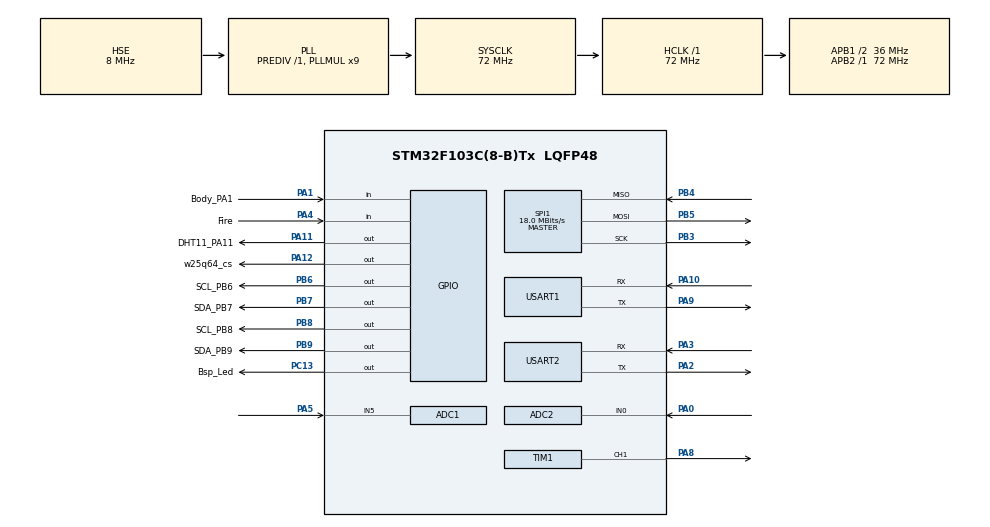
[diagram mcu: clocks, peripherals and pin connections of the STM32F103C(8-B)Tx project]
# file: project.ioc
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ADC1.Channel-6\#ChannelRegularConversion=ADC_CHANNEL_5
ADC1.ContinuousConvMode=DISABLE
ADC1.NbrOfConversionFlag=1
ADC1.Rank-6\#ChannelRegularConversion=1
ADC1.SamplingTime-6\#ChannelRegularConversion=ADC_SAMPLETIME_28CYCLES_5
ADC1.master=1
ADC2.Channel-0\#ChannelRegularConversion=ADC_CHANNEL_0
ADC2.ContinuousConvMode=DISABLE
ADC2.NbrOfConversionFlag=1
ADC2.Rank-0\#ChannelRegularConversion=1
ADC2.SamplingTime-0\#ChannelRegularConversion=ADC_SAMPLETIME_55CYCLES_5
Dma.Request0=USART1_RX
Dma.USART1_RX.0.Direction=DMA_PERIPH_TO_MEMORY
Dma.USART1_RX.0.Instance=DMA1_Channel5
Dma.USART1_RX.0.MemDataAlignment=DMA_MDATAALIGN_BYTE
Dma.USART1_RX.0.MemInc=DMA_MINC_ENABLE
Dma.USART1_RX.0.Mode=DMA_NORMAL
Dma.USART1_RX.0.PeriphDataAlignment=DMA_PDATAALIGN_BYTE
Dma.USART1_RX.0.PeriphInc=DMA_PINC_DISABLE
Dma.USART1_RX.0.Priority=DMA_PRIORITY_MEDIUM
FREERTOS.Tasks01=All_TaskInit,24,128,Start_TaskInit,Default,NULL,Dynamic,NULL,NULL
FREERTOS.configCHECK_FOR_STACK_OVERFLOW=2
FREERTOS.configTOTAL_HEAP_SIZE=12*1024
FREERTOS.configUSE_IDLE_HOOK=1
FREERTOS.configUSE_STATS_FORMATTING_FUNCTIONS=1
Mcu.Family=STM32F1
Mcu.Name=STM32F103C(8-B)Tx
Mcu.Package=LQFP48
NVIC.DMA1_Channel5_IRQn=true\:5\:0\:false\:false\:true\:true\:false\:true\:true
NVIC.PriorityGroup=NVIC_PRIORITYGROUP_4
NVIC.TIM2_IRQn=true\:5\:0\:false\:false\:true\:true\:true\:true\:true
NVIC.TIM4_IRQn=true\:0\:0\:true\:false\:true\:false\:false\:true\:true
NVIC.TimeBase=TIM4_IRQn
NVIC.TimeBaseIP=TIM4
NVIC.USART1_IRQn=true\:5\:0\:false\:false\:true\:true\:true\:true\:true
NVIC.USART2_IRQn=true\:5\:0\:false\:false\:true\:true\:true\:true\:true
PA0-WKUP.Signal=ADCx_IN0
PA1.GPIO_Label=Body_PA1
PA1.GPIO_PuPd=GPIO_PULLDOWN
PA1.Signal=GPIO_Input
PA10.Mode=Asynchronous
PA10.Signal=USART1_RX
PA11.GPIO_Label=DHT11_PA11
PA11.GPIO_ModeDefaultOutputPP=GPIO_MODE_OUTPUT_PP
PA11.GPIO_PuPd=GPIO_NOPULL
PA11.Signal=GPIO_Output
PA12.GPIO_Label=w25q64_cs
PA12.GPIO_PuPd=GPIO_PULLUP
PA12.GPIO_Speed=GPIO_SPEED_FREQ_HIGH
PA12.PinState=GPIO_PIN_SET
PA12.Signal=GPIO_Output
PA13.Mode=Serial_Wire
PA13.Signal=SYS_JTMS-SWDIO
PA14.Mode=Serial_Wire
PA14.Signal=SYS_JTCK-SWCLK
PA2.Mode=Asynchronous
PA2.Signal=USART2_TX
PA3.Mode=Asynchronous
PA3.Signal=USART2_RX
PA4.GPIO_Label=Fire
PA4.GPIO_PuPd=GPIO_PULLUP
PA4.Signal=GPIO_Input
PA5.Signal=ADCx_IN5
PA8.Signal=S_TIM1_CH1
PA9.Mode=Asynchronous
PA9.Signal=USART1_TX
PB3.Mode=Full_Duplex_Master
PB3.Signal=SPI1_SCK
PB4.Mode=Full_Duplex_Master
PB4.Signal=SPI1_MISO
PB5.Mode=Full_Duplex_Master
PB5.Signal=SPI1_MOSI
PB6.GPIO_Label=SCL_PB6
PB6.GPIO_ModeDefaultOutputPP=GPIO_MODE_OUTPUT_OD
PB6.GPIO_PuPd=GPIO_NOPULL
PB6.GPIO_Speed=GPIO_SPEED_FREQ_MEDIUM
PB6.PinState=GPIO_PIN_SET
PB6.Signal=GPIO_Output
PB7.GPIO_Label=SDA_PB7
PB7.GPIO_ModeDefaultOutputPP=GPIO_MODE_OUTPUT_OD
PB7.GPIO_PuPd=GPIO_NOPULL
PB7.GPIO_Speed=GPIO_SPEED_FREQ_MEDIUM
PB7.PinState=GPIO_PIN_SET
PB7.Signal=GPIO_Output
PB8.GPIO_Label=SCL_PB8
PB8.GPIO_ModeDefaultOutputPP=GPIO_MODE_OUTPUT_OD
PB8.GPIO_PuPd=GPIO_NOPULL
PB8.GPIO_Speed=GPIO_SPEED_FREQ_HIGH
PB8.Signal=GPIO_Output
PB9.GPIO_Label=SDA_PB9
PB9.GPIO_ModeDefaultOutputPP=GPIO_MODE_OUTPUT_OD
PB9.GPIO_PuPd=GPIO_NOPULL
PB9.GPIO_Speed=GPIO_SPEED_FREQ_HIGH
PB9.Signal=GPIO_Output
PC13-TAMPER-RTC.GPIO_Label=Bsp_Led
PC13-TAMPER-RTC.GPIO_ModeDefaultOutputPP=GPIO_MODE_OUTPUT_PP
PC13-TAMPER-RTC.GPIO_Speed=GPIO_SPEED_FREQ_MEDIUM
PC13-TAMPER-RTC.PinState=GPIO_PIN_SET
PC13-TAMPER-RTC.Signal=GPIO_Output
PC14-OSC32_IN.Mode=LSE-External-Oscillator
PC14-OSC32_IN.Signal=RCC_OSC32_IN
PC15-OSC32_OUT.Mode=LSE-External-Oscillator
PC15-OSC32_OUT.Signal=RCC_OSC32_OUT
PD0-OSC_IN.Mode=HSE-External-Oscillator
PD0-OSC_IN.Signal=RCC_OSC_IN
PD1-OSC_OUT.Mode=HSE-External-Oscillator
PD1-OSC_OUT.Signal=RCC_OSC_OUT
ProjectManager.HeapSize=0x000
ProjectManager.StackSize=0x400
ProjectManager.TargetToolchain=MDK-ARM V5.32
RCC.ADCPresc=RCC_ADCPCLK2_DIV6
RCC.AHBFreq_Value=72000000
RCC.APB1CLKDivider=RCC_HCLK_DIV2
RCC.APB1Freq_Value=36000000
RCC.APB1TimFreq_Value=72000000
RCC.APB2Freq_Value=72000000
RCC.APB2TimFreq_Value=72000000
RCC.HCLKFreq_Value=72000000
RCC.PLLMUL=RCC_PLL_MUL9
RCC.PLLSourceVirtual=RCC_PLLSOURCE_HSE
RCC.SYSCLKFreq_VALUE=72000000
RCC.SYSCLKSource=RCC_SYSCLKSOURCE_PLLCLK
RCC.USBFreq_Value=72000000
SH.ADCx_IN0.0=ADC2_IN0,IN0
SH.ADCx_IN5.0=ADC1_IN5,IN5
SH.S_TIM1_CH1.0=TIM1_CH1,PWM Generation1 CH1
SPI1.BaudRatePrescaler=SPI_BAUDRATEPRESCALER_4
SPI1.CalculateBaudRate=18.0 MBits/s
SPI1.Direction=SPI_DIRECTION_2LINES
SPI1.Mode=SPI_MODE_MASTER
SPI1.VirtualType=VM_MASTER
TIM1.Channel-PWM\ Generation1\ CH1=TIM_CHANNEL_1
TIM1.Period=1000-1
TIM1.Prescaler=72-1
TIM2.Period=100-1
TIM2.Prescaler=7200-1
USART1.VirtualMode=VM_ASYNC
USART2.VirtualMode=VM_ASYNC
VP_FREERTOS_VS_CMSIS_V2.Mode=CMSIS_V2
VP_SYS_VS_tim4.Mode=TIM4
VP_TIM1_VS_ClockSourceINT.Mode=Internal
VP_TIM2_VS_ClockSourceINT.Mode=Internal
board=custom

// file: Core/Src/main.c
/* USER CODE BEGIN Header */
/**
 ******************************************************************************
 * @file           : main.c
 * @brief          : Main program body
 ******************************************************************************
 * @attention
 *
 * Copyright (c) 2025 STMicroelectronics.
 * All rights reserved.
 *
 * This software is licensed under terms that can be found in the LICENSE file
 * in the root directory of this software component.
 * If no LICENSE file comes with this software, it is provided AS-IS.
 *
 ******************************************************************************
 */
/* USER CODE END Header */
#include "main.h"
#include "cmsis_os.h"
#include "adc.h"
#include "dma.h"
#include "spi.h"
#include "tim.h"
#include "usart.h"
#include "gpio.h"

/* USER CODE BEGIN Includes */
#include "Time.h"
/* USER CODE END Includes */

void SystemClock_Config(void);
void MX_FREERTOS_Init(void);

int main(void)
{

  /* MCU Configuration--------------------------------------------------------*/

  /* Reset of all peripherals, Initializes the Flash interface and the Systick. */
  HAL_Init();

  /* Configure the system clock */
  SystemClock_Config();

  /* Initialize all configured peripherals */
  MX_GPIO_Init();
  MX_DMA_Init();
  MX_USART1_UART_Init();
  MX_USART2_UART_Init();
  MX_TIM2_Init();
  MX_TIM1_Init();
  MX_ADC1_Init();
  MX_ADC2_Init();
  MX_SPI1_Init();
  /* USER CODE BEGIN 2 */
  // �ȴ�У׼���
  HAL_ADCEx_Calibration_Start(&hadc1);
  HAL_ADCEx_Calibration_Start(&hadc2);
  /* USER CODE END 2 */

  /* Init scheduler */
  osKernelInitialize();  /* Call init function for freertos objects (in cmsis_os2.c) */
  MX_FREERTOS_Init();

  /* Start scheduler */
  osKernelStart();

  /* We should never get here as control is now taken by the scheduler */

  /* Infinite loop */
  while (1)
  {

  }
}

void SystemClock_Config(void)
{
  RCC_OscInitTypeDef RCC_OscInitStruct = {0};
  RCC_ClkInitTypeDef RCC_ClkInitStruct = {0};
  RCC_PeriphCLKInitTypeDef PeriphClkInit = {0};

  /** Initializes the RCC Oscillators according to the specified parameters
  * in the RCC_OscInitTypeDef structure.
  */
  RCC_OscInitStruct.OscillatorType = RCC_OSCILLATORTYPE_HSE;
  RCC_OscInitStruct.HSEState = RCC_HSE_ON;
  RCC_OscInitStruct.HSEPredivValue = RCC_HSE_PREDIV_DIV1;
  RCC_OscInitStruct.HSIState = RCC_HSI_ON;
  RCC_OscInitStruct.PLL.PLLState = RCC_PLL_ON;
  RCC_OscInitStruct.PLL.PLLSource = RCC_PLLSOURCE_HSE;
  RCC_OscInitStruct.PLL.PLLMUL = RCC_PLL_MUL9;
  if (HAL_RCC_OscConfig(&RCC_OscInitStruct) != HAL_OK)
  {
    Error_Handler();
  }

  /** Initializes the CPU, AHB and APB buses clocks
  */
  RCC_ClkInitStruct.ClockType = RCC_CLOCKTYPE_HCLK|RCC_CLOCKTYPE_SYSCLK
                              |RCC_CLOCKTYPE_PCLK1|RCC_CLOCKTYPE_PCLK2;
  RCC_ClkInitStruct.SYSCLKSource = RCC_SYSCLKSOURCE_PLLCLK;
  RCC_ClkInitStruct.AHBCLKDivider = RCC_SYSCLK_DIV1;
  RCC_ClkInitStruct.APB1CLKDivider = RCC_HCLK_DIV2;
  RCC_ClkInitStruct.APB2CLKDivider = RCC_HCLK_DIV1;

  if (HAL_RCC_ClockConfig(&RCC_ClkInitStruct, FLASH_LATENCY_2) != HAL_OK)
  {
    Error_Handler();
  }
  PeriphClkInit.PeriphClockSelection = RCC_PERIPHCLK_ADC;
  PeriphClkInit.AdcClockSelection = RCC_ADCPCLK2_DIV6;
  if (HAL_RCCEx_PeriphCLKConfig(&PeriphClkInit) != HAL_OK)
  {
    Error_Handler();
  }
}

void HAL_TIM_PeriodElapsedCallback(TIM_HandleTypeDef *htim)
{
  if (htim->Instance == TIM4)
  {
    HAL_IncTick();
  }
  /* USER CODE BEGIN Callback 1 */
  if (htim->Instance == TIM2)
  {
    Get_Time();
  }
  /* USER CODE END Callback 1 */
}

void Error_Handler(void)
{
  __disable_irq();
  while (1)
  {
  }
}

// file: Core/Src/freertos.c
/* USER CODE BEGIN Header */
/**
 ******************************************************************************
 * File Name          : freertos.c
 * Description        : Code for freertos applications
 ******************************************************************************
 * @attention
 *
 * Copyright (c) 2025 STMicroelectronics.
 * All rights reserved.
 *
 * This software is licensed under terms that can be found in the LICENSE file
 * in the root directory of this software component.
 * If no LICENSE file comes with this software, it is provided AS-IS.
 *
 ******************************************************************************
 */
/* USER CODE END Header */

#include "FreeRTOS.h"
#include "task.h"
#include "main.h"
#include "cmsis_os.h"

/* USER CODE BEGIN Includes */
#include "My_Task.h"
/* USER CODE END Includes */

/* Definitions for All_TaskInit */
osThreadId_t All_TaskInitHandle;
const osThreadAttr_t All_TaskInit_attributes = {
    .name = "All_TaskInit",
    .stack_size = 128 * 4,
    .priority = (osPriority_t)osPriorityNormal,
};

void Start_TaskInit(void *argument);

void MX_FREERTOS_Init(void); /* (MISRA C 2004 rule 8.1) */

/* Hook prototypes */
void vApplicationIdleHook(void);
void vApplicationStackOverflowHook(xTaskHandle xTask, signed char *pcTaskName);

/* USER CODE BEGIN 2 */
void vApplicationIdleHook(void)
{
  /* vApplicationIdleHook() will only be called if configUSE_IDLE_HOOK is set
  to 1 in FreeRTOSConfig.h. It will be called on each iteration of the idle
  task. It is essential that code added to this hook function never attempts
  to block in any way (for example, call xQueueReceive() with a block time
  specified, or call vTaskDelay()). If the application makes use of the
  vTaskDelete() API function (as this demo application does) then it is also
  important that vApplicationIdleHook() is permitted to return to its calling
  function, because it is the responsibility of the idle task to clean up
  memory allocated by the kernel to any task that has since been deleted. */
}
/* USER CODE END 2 */

/* USER CODE BEGIN 4 */
void vApplicationStackOverflowHook(xTaskHandle xTask, signed char *pcTaskName)
{
  /* Run time stack overflow checking is performed if
  configCHECK_FOR_STACK_OVERFLOW is defined to 1 or 2. This hook function is
  called if a stack overflow is detected. */
}
/* USER CODE END 4 */

void MX_FREERTOS_Init(void)
{

  /* Create the thread(s) */
  /* creation of All_TaskInit */
  All_TaskInitHandle = osThreadNew(Start_TaskInit, NULL, &All_TaskInit_attributes);

}

void Start_TaskInit(void *argument)
{
  /* USER CODE BEGIN Start_TaskInit */

  My_Drivers_Init();
  // 删除此任务
  vTaskDelete(NULL);
  vTaskDelay(portMAX_DELAY);
  /* Infinite loop */
  for (;;)
  {
  }
  /* USER CODE END Start_TaskInit */
}
